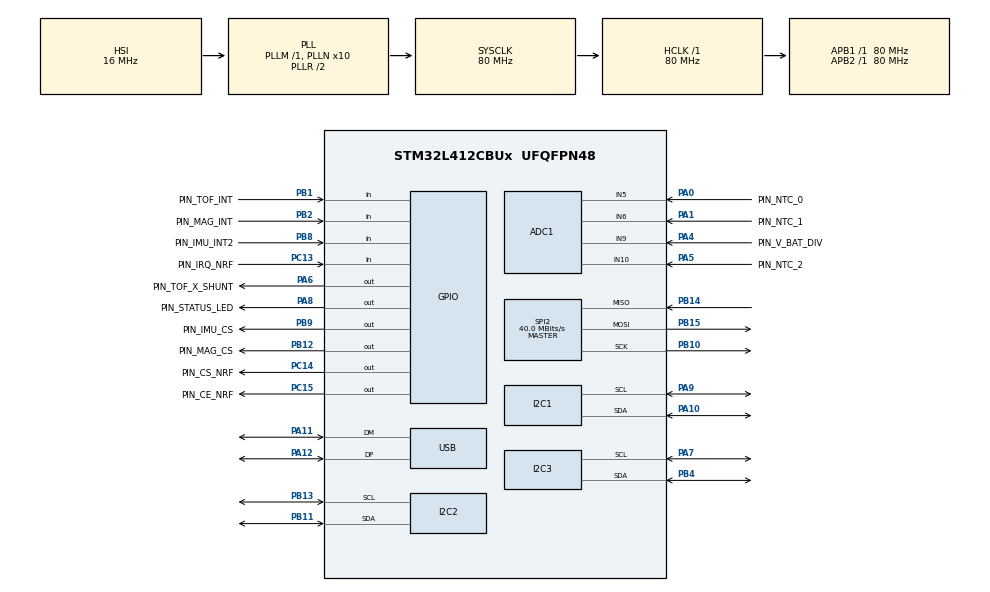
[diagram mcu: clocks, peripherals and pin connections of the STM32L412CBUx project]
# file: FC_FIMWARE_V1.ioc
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ADC1.Channel-1\#ChannelRegularConversion=ADC_CHANNEL_9
ADC1.NbrOfConversionFlag=1
ADC1.OffsetNumber-1\#ChannelRegularConversion=ADC_OFFSET_NONE
ADC1.Rank-1\#ChannelRegularConversion=1
ADC1.SamplingTime-1\#ChannelRegularConversion=ADC_SAMPLETIME_2CYCLES_5
ADC1.master=1
I2C1.Timing=0x10D19CE4
I2C2.Timing=0x10D19CE4
I2C3.Timing=0x10D19CE4
Mcu.Family=STM32L4
Mcu.Name=STM32L412CBUx
Mcu.Package=UFQFPN48
NVIC.PriorityGroup=NVIC_PRIORITYGROUP_4
NVIC.SPI2_IRQn=true\:0\:0\:false\:false\:true\:true\:true\:true
NVIC.USB_IRQn=true\:0\:0\:false\:false\:true\:false\:true\:true
PA0.GPIO_Label=PIN_NTC_0
PA0.Signal=ADCx_IN5
PA1.GPIO_Label=PIN_NTC_1
PA1.Signal=ADCx_IN6
PA10.Mode=I2C
PA10.Signal=I2C1_SDA
PA11.Mode=Device
PA11.Signal=USB_DM
PA12.Mode=Device
PA12.Signal=USB_DP
PA13\ (JTMS/SWDIO).Mode=Serial_Wire
PA13\ (JTMS/SWDIO).Signal=SYS_JTMS-SWDIO
PA14\ (JTCK/SWCLK).GPIO_Label=PIN_IMU_INT1
PA14\ (JTCK/SWCLK).Mode=Serial_Wire
PA14\ (JTCK/SWCLK).Signal=SYS_JTCK-SWCLK
PA4.GPIO_Label=PIN_V_BAT_DIV
PA4.Signal=ADCx_IN9
PA5.GPIO_Label=PIN_NTC_2
PA5.Signal=ADCx_IN10
PA6.GPIO_Label=PIN_TOF_X_SHUNT
PA6.Signal=GPIO_Output
PA7.Mode=I2C
PA7.Signal=I2C3_SCL
PA8.GPIO_Label=PIN_STATUS_LED
PA8.Signal=GPIO_Output
PA9.Mode=I2C
PA9.Signal=I2C1_SCL
PB1.GPIO_Label=PIN_TOF_INT
PB1.Signal=GPIO_Input
PB10.Mode=Full_Duplex_Master
PB10.Signal=SPI2_SCK
PB11.Mode=I2C
PB11.Signal=I2C2_SDA
PB12.GPIO_Label=PIN_MAG_CS
PB12.Signal=GPIO_Output
PB13.Mode=I2C
PB13.Signal=I2C2_SCL
PB14.Mode=Full_Duplex_Master
PB14.Signal=SPI2_MISO
PB15.Mode=Full_Duplex_Master
PB15.Signal=SPI2_MOSI
PB2.GPIO_Label=PIN_MAG_INT
PB2.Signal=GPIO_Input
PB4\ (NJTRST).Mode=I2C
PB4\ (NJTRST).Signal=I2C3_SDA
PB8.GPIO_Label=PIN_IMU_INT2
PB8.Signal=GPIO_Input
PB9.GPIO_Label=PIN_IMU_CS
PB9.Signal=GPIO_Output
PC13.GPIO_Label=PIN_IRQ_NRF
PC13.Signal=GPIO_Input
PC14-OSC32_IN\ (PC14).GPIO_Label=PIN_CS_NRF
PC14-OSC32_IN\ (PC14).Signal=GPIO_Output
PC15-OSC32_OUT\ (PC15).GPIO_Label=PIN_CE_NRF
PC15-OSC32_OUT\ (PC15).Signal=GPIO_Output
PH0-OSC_IN\ (PH0).Mode=HSE-External-Oscillator
PH0-OSC_IN\ (PH0).Signal=RCC_OSC_IN
PH1-OSC_OUT\ (PH1).Mode=HSE-External-Oscillator
PH1-OSC_OUT\ (PH1).Signal=RCC_OSC_OUT
ProjectManager.HeapSize=0x200
ProjectManager.StackSize=0x400
ProjectManager.TargetToolchain=CMake
RCC.ADCFreq_Value=80000000
RCC.AHBFreq_Value=80000000
RCC.APB1Freq_Value=80000000
RCC.APB1TimFreq_Value=80000000
RCC.APB2Freq_Value=80000000
RCC.APB2TimFreq_Value=80000000
RCC.CortexFreq_Value=80000000
RCC.HCLKFreq_Value=80000000
RCC.HSE_VALUE=12000000
RCC.HSI48_VALUE=48000000
RCC.HSI_VALUE=16000000
RCC.LSE_VALUE=32768
RCC.MSIClockRange=RCC_MSIRANGE_11
RCC.MSI_VALUE=48000000
RCC.PLLN=10
RCC.PLLSourceVirtual=RCC_PLLSOURCE_HSI
RCC.SYSCLKFreq_VALUE=80000000
RCC.SYSCLKSource=RCC_SYSCLKSOURCE_PLLCLK
RCC.USBFreq_Value=48000000
RCC.VCOOutputFreq_Value=160000000
SH.ADCx_IN10.0=ADC1_IN10,IN10-Single-Ended
SH.ADCx_IN5.0=ADC1_IN5,IN5-Single-Ended
SH.ADCx_IN6.0=ADC1_IN6,IN6-Single-Ended
SH.ADCx_IN9.0=ADC1_IN9,IN9-Single-Ended
SPI2.CalculateBaudRate=40.0 MBits/s
SPI2.DataSize=SPI_DATASIZE_8BIT
SPI2.Direction=SPI_DIRECTION_2LINES
SPI2.Mode=SPI_MODE_MASTER
SPI2.VirtualType=VM_MASTER
TIM2.AutoReloadPreload=TIM_AUTORELOAD_PRELOAD_DISABLE
TIM2.ClockDivision=TIM_CLOCKDIVISION_DIV1
TIM2.Prescaler=79
USB_DEVICE.CLASS_NAME_FS=CDC
USB_DEVICE.PRODUCT_STRING_CDC_FS=FC_V1
USB_DEVICE.USBD_DEBUG_LEVEL=3
USB_DEVICE.USBD_LPM_ENABLED=0
USB_DEVICE.VirtualMode=Cdc
USB_DEVICE.VirtualModeFS=Cdc_FS
VP_TIM2_VS_ClockSourceINT.Mode=Internal
VP_USB_DEVICE_VS_USB_DEVICE_CDC_FS.Mode=CDC_FS
board=custom

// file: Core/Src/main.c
/* USER CODE BEGIN Header */
/**
 ******************************************************************************
 * @file           : main.c
 * @brief          : Main program body
 ******************************************************************************
 * @attention
 *
 * Copyright (c) 2024 STMicroelectronics.
 * All rights reserved.
 *
 * This software is licensed under terms that can be found in the LICENSE file
 * in the root directory of this software component.
 * If no LICENSE file comes with this software, it is provided AS-IS.
 *
 * ./dfu-util/dfu-util -a 0 -i 0 -s 0x08000000:leave -D ./build/Debug/FC_FIMWARE_V1.bin
 *
 ******************************************************************************
 */
/* USER CODE END Header */
#include "main.h"
#include "usb_device.h"

/* USER CODE BEGIN Includes */
#include "usbd_cdc_if.h"
#include <stdio.h>
// #include ".\sensors\icm62670p\icm42670p.c"
// // #include "icm42670p.h"
#include "console.c" //needs to be here to compile
#include "console.h"
/* USER CODE END Includes */

ADC_HandleTypeDef hadc1;

I2C_HandleTypeDef hi2c1;
I2C_HandleTypeDef hi2c2;
I2C_HandleTypeDef hi2c3;

SPI_HandleTypeDef hspi2;

TIM_HandleTypeDef htim2;

void SystemClock_Config(void);
static void MX_GPIO_Init(void);
static void MX_ADC1_Init(void);
static void MX_I2C1_Init(void);
static void MX_I2C3_Init(void);
static void MX_SPI2_Init(void);
static void MX_I2C2_Init(void);
static void MX_TIM2_Init(void);

int main(void)
{

  /* MCU Configuration--------------------------------------------------------*/

  /* Reset of all peripherals, Initializes the Flash interface and the Systick. */
  HAL_Init();

  /* Configure the system clock */
  SystemClock_Config();

  /* Initialize all configured peripherals */
  MX_GPIO_Init();
  MX_ADC1_Init();
  MX_I2C1_Init();
  MX_I2C3_Init();
  MX_SPI2_Init();
  MX_USB_DEVICE_Init();
  MX_I2C2_Init();
  MX_TIM2_Init();
  /* USER CODE BEGIN 2 */
  // console_init();
  // set all SPI CS high
  HAL_GPIO_WritePin(PIN_CS_NRF_GPIO_Port, PIN_CS_NRF_Pin, GPIO_PIN_SET);
  HAL_GPIO_WritePin(PIN_IMU_CS_GPIO_Port, PIN_IMU_CS_Pin, GPIO_PIN_SET);
  // init sensors
  // icm_init();
  HAL_Delay(500);
  /* USER CODE END 2 */

  /* Infinite loop */
  /* USER CODE BEGIN WHILE */
  while (1)
  {
    // HAL_Delay(10);
    // toggle_status_LED(PIN_STATUS_LED_GPIO_Port, PIN_STATUS_LED_Pin);
    // console_check_for_messages();
    // debugf("oi\n");
    uint8_t TxBuffer[] = "Hello World! From STM32 USB CDC Device To Virtual COM Port\r\n";
    CDC_Transmit_FS(TxBuffer, sizeof(TxBuffer));
    // struct icm_data *data = icm_read_data();
    // free(data);

    // icm_read_data_fifo();

    /* USER CODE END WHILE */

  }
}

void SystemClock_Config(void)
{
  RCC_OscInitTypeDef RCC_OscInitStruct = {0};
  RCC_ClkInitTypeDef RCC_ClkInitStruct = {0};

  /** Configure the main internal regulator output voltage
   */
  if (HAL_PWREx_ControlVoltageScaling(PWR_REGULATOR_VOLTAGE_SCALE1) != HAL_OK)
  {
    Error_Handler();
  }

  /** Initializes the RCC Oscillators according to the specified parameters
   * in the RCC_OscInitTypeDef structure.
   */
  RCC_OscInitStruct.OscillatorType = RCC_OSCILLATORTYPE_HSI | RCC_OSCILLATORTYPE_MSI;
  RCC_OscInitStruct.HSIState = RCC_HSI_ON;
  RCC_OscInitStruct.HSICalibrationValue = RCC_HSICALIBRATION_DEFAULT;
  RCC_OscInitStruct.MSIState = RCC_MSI_ON;
  RCC_OscInitStruct.MSICalibrationValue = 0;
  RCC_OscInitStruct.MSIClockRange = RCC_MSIRANGE_11;
  RCC_OscInitStruct.PLL.PLLState = RCC_PLL_ON;
  RCC_OscInitStruct.PLL.PLLSource = RCC_PLLSOURCE_HSI;
  RCC_OscInitStruct.PLL.PLLM = 1;
  RCC_OscInitStruct.PLL.PLLN = 10;
  RCC_OscInitStruct.PLL.PLLQ = RCC_PLLQ_DIV2;
  RCC_OscInitStruct.PLL.PLLR = RCC_PLLR_DIV2;
  if (HAL_RCC_OscConfig(&RCC_OscInitStruct) != HAL_OK)
  {
    Error_Handler();
  }

  /** Initializes the CPU, AHB and APB buses clocks
   */
  RCC_ClkInitStruct.ClockType = RCC_CLOCKTYPE_HCLK | RCC_CLOCKTYPE_SYSCLK | RCC_CLOCKTYPE_PCLK1 | RCC_CLOCKTYPE_PCLK2;
  RCC_ClkInitStruct.SYSCLKSource = RCC_SYSCLKSOURCE_PLLCLK;
  RCC_ClkInitStruct.AHBCLKDivider = RCC_SYSCLK_DIV1;
  RCC_ClkInitStruct.APB1CLKDivider = RCC_HCLK_DIV1;
  RCC_ClkInitStruct.APB2CLKDivider = RCC_HCLK_DIV1;

  if (HAL_RCC_ClockConfig(&RCC_ClkInitStruct, FLASH_LATENCY_4) != HAL_OK)
  {
    Error_Handler();
  }
}

static void MX_ADC1_Init(void)
{

  ADC_MultiModeTypeDef multimode = {0};
  ADC_ChannelConfTypeDef sConfig = {0};

  /** Common config
   */
  hadc1.Instance = ADC1;
  hadc1.Init.ClockPrescaler = ADC_CLOCK_ASYNC_DIV1;
  hadc1.Init.Resolution = ADC_RESOLUTION_12B;
  hadc1.Init.DataAlign = ADC_DATAALIGN_RIGHT;
  hadc1.Init.ScanConvMode = ADC_SCAN_DISABLE;
  hadc1.Init.EOCSelection = ADC_EOC_SINGLE_CONV;
  hadc1.Init.LowPowerAutoWait = DISABLE;
  hadc1.Init.ContinuousConvMode = DISABLE;
  hadc1.Init.NbrOfConversion = 1;
  hadc1.Init.DiscontinuousConvMode = DISABLE;
  hadc1.Init.ExternalTrigConv = ADC_SOFTWARE_START;
  hadc1.Init.ExternalTrigConvEdge = ADC_EXTERNALTRIGCONVEDGE_NONE;
  hadc1.Init.DMAContinuousRequests = DISABLE;
  hadc1.Init.Overrun = ADC_OVR_DATA_PRESERVED;
  hadc1.Init.OversamplingMode = DISABLE;
  if (HAL_ADC_Init(&hadc1) != HAL_OK)
  {
    Error_Handler();
  }

  /** Configure the ADC multi-mode
   */
  multimode.Mode = ADC_MODE_INDEPENDENT;
  if (HAL_ADCEx_MultiModeConfigChannel(&hadc1, &multimode) != HAL_OK)
  {
    Error_Handler();
  }

  /** Configure Regular Channel
   */
  sConfig.Channel = ADC_CHANNEL_9;
  sConfig.Rank = ADC_REGULAR_RANK_1;
  sConfig.SamplingTime = ADC_SAMPLETIME_2CYCLES_5;
  sConfig.SingleDiff = ADC_SINGLE_ENDED;
  sConfig.OffsetNumber = ADC_OFFSET_NONE;
  sConfig.Offset = 0;
  if (HAL_ADC_ConfigChannel(&hadc1, &sConfig) != HAL_OK)
  {
    Error_Handler();
  }
}

static void MX_I2C1_Init(void)
{

  hi2c1.Instance = I2C1;
  hi2c1.Init.Timing = 0x10D19CE4;
  hi2c1.Init.OwnAddress1 = 0;
  hi2c1.Init.AddressingMode = I2C_ADDRESSINGMODE_7BIT;
  hi2c1.Init.DualAddressMode = I2C_DUALADDRESS_DISABLE;
  hi2c1.Init.OwnAddress2 = 0;
  hi2c1.Init.OwnAddress2Masks = I2C_OA2_NOMASK;
  hi2c1.Init.GeneralCallMode = I2C_GENERALCALL_DISABLE;
  hi2c1.Init.NoStretchMode = I2C_NOSTRETCH_DISABLE;
  if (HAL_I2C_Init(&hi2c1) != HAL_OK)
  {
    Error_Handler();
  }

  /** Configure Analogue filter
   */
  if (HAL_I2CEx_ConfigAnalogFilter(&hi2c1, I2C_ANALOGFILTER_ENABLE) != HAL_OK)
  {
    Error_Handler();
  }

  /** Configure Digital filter
   */
  if (HAL_I2CEx_ConfigDigitalFilter(&hi2c1, 0) != HAL_OK)
  {
    Error_Handler();
  }
}

static void MX_I2C2_Init(void)
{

  hi2c2.Instance = I2C2;
  hi2c2.Init.Timing = 0x10D19CE4;
  hi2c2.Init.OwnAddress1 = 0;
  hi2c2.Init.AddressingMode = I2C_ADDRESSINGMODE_7BIT;
  hi2c2.Init.DualAddressMode = I2C_DUALADDRESS_DISABLE;
  hi2c2.Init.OwnAddress2 = 0;
  hi2c2.Init.OwnAddress2Masks = I2C_OA2_NOMASK;
  hi2c2.Init.GeneralCallMode = I2C_GENERALCALL_DISABLE;
  hi2c2.Init.NoStretchMode = I2C_NOSTRETCH_DISABLE;
  if (HAL_I2C_Init(&hi2c2) != HAL_OK)
  {
    Error_Handler();
  }

  /** Configure Analogue filter
   */
  if (HAL_I2CEx_ConfigAnalogFilter(&hi2c2, I2C_ANALOGFILTER_ENABLE) != HAL_OK)
  {
    Error_Handler();
  }

  /** Configure Digital filter
   */
  if (HAL_I2CEx_ConfigDigitalFilter(&hi2c2, 0) != HAL_OK)
  {
    Error_Handler();
  }
}

static void MX_I2C3_Init(void)
{

  hi2c3.Instance = I2C3;
  hi2c3.Init.Timing = 0x10D19CE4;
  hi2c3.Init.OwnAddress1 = 0;
  hi2c3.Init.AddressingMode = I2C_ADDRESSINGMODE_7BIT;
  hi2c3.Init.DualAddressMode = I2C_DUALADDRESS_DISABLE;
  hi2c3.Init.OwnAddress2 = 0;
  hi2c3.Init.OwnAddress2Masks = I2C_OA2_NOMASK;
  hi2c3.Init.GeneralCallMode = I2C_GENERALCALL_DISABLE;
  hi2c3.Init.NoStretchMode = I2C_NOSTRETCH_DISABLE;
  if (HAL_I2C_Init(&hi2c3) != HAL_OK)
  {
    Error_Handler();
  }

  /** Configure Analogue filter
   */
  if (HAL_I2CEx_ConfigAnalogFilter(&hi2c3, I2C_ANALOGFILTER_ENABLE) != HAL_OK)
  {
    Error_Handler();
  }

  /** Configure Digital filter
   */
  if (HAL_I2CEx_ConfigDigitalFilter(&hi2c3, 0) != HAL_OK)
  {
    Error_Handler();
  }
}

static void MX_SPI2_Init(void)
{

  /* SPI2 parameter configuration*/
  hspi2.Instance = SPI2;
  hspi2.Init.Mode = SPI_MODE_MASTER;
  hspi2.Init.Direction = SPI_DIRECTION_2LINES;
  hspi2.Init.DataSize = SPI_DATASIZE_8BIT;
  hspi2.Init.CLKPolarity = SPI_POLARITY_LOW;
  hspi2.Init.CLKPhase = SPI_PHASE_1EDGE;
  hspi2.Init.NSS = SPI_NSS_SOFT;
  hspi2.Init.BaudRatePrescaler = SPI_BAUDRATEPRESCALER_2;
  hspi2.Init.FirstBit = SPI_FIRSTBIT_MSB;
  hspi2.Init.TIMode = SPI_TIMODE_DISABLE;
  hspi2.Init.CRCCalculation = SPI_CRCCALCULATION_DISABLE;
  hspi2.Init.CRCPolynomial = 7;
  hspi2.Init.CRCLength = SPI_CRC_LENGTH_DATASIZE;
  hspi2.Init.NSSPMode = SPI_NSS_PULSE_ENABLE;
  if (HAL_SPI_Init(&hspi2) != HAL_OK)
  {
    Error_Handler();
  }
}

static void MX_TIM2_Init(void)
{

  TIM_ClockConfigTypeDef sClockSourceConfig = {0};
  TIM_MasterConfigTypeDef sMasterConfig = {0};

  htim2.Instance = TIM2;
  htim2.Init.Prescaler = 79;
  htim2.Init.CounterMode = TIM_COUNTERMODE_UP;
  htim2.Init.Period = 4294967295;
  htim2.Init.ClockDivision = TIM_CLOCKDIVISION_DIV1;
  htim2.Init.AutoReloadPreload = TIM_AUTORELOAD_PRELOAD_DISABLE;
  if (HAL_TIM_Base_Init(&htim2) != HAL_OK)
  {
    Error_Handler();
  }
  sClockSourceConfig.ClockSource = TIM_CLOCKSOURCE_INTERNAL;
  if (HAL_TIM_ConfigClockSource(&htim2, &sClockSourceConfig) != HAL_OK)
  {
    Error_Handler();
  }
  sMasterConfig.MasterOutputTrigger = TIM_TRGO_RESET;
  sMasterConfig.MasterSlaveMode = TIM_MASTERSLAVEMODE_DISABLE;
  if (HAL_TIMEx_MasterConfigSynchronization(&htim2, &sMasterConfig) != HAL_OK)
  {
    Error_Handler();
  }
  /* USER CODE BEGIN TIM2_Init 2 */
  HAL_TIM_Base_Start(&htim2);
  /* USER CODE END TIM2_Init 2 */
}

static void MX_GPIO_Init(void)
{
  GPIO_InitTypeDef GPIO_InitStruct = {0};

  /* GPIO Ports Clock Enable */
  __HAL_RCC_GPIOC_CLK_ENABLE();
  __HAL_RCC_GPIOH_CLK_ENABLE();
  __HAL_RCC_GPIOA_CLK_ENABLE();
  __HAL_RCC_GPIOB_CLK_ENABLE();

  /*Configure GPIO pin Output Level */
  HAL_GPIO_WritePin(GPIOC, PIN_CS_NRF_Pin | PIN_CE_NRF_Pin, GPIO_PIN_RESET);

  /*Configure GPIO pin Output Level */
  HAL_GPIO_WritePin(GPIOA, PIN_TOF_X_SHUNT_Pin | PIN_STATUS_LED_Pin, GPIO_PIN_RESET);

  /*Configure GPIO pin Output Level */
  HAL_GPIO_WritePin(GPIOB, PIN_MAG_CS_Pin | PIN_IMU_CS_Pin, GPIO_PIN_RESET);

  /*Configure GPIO pin : PIN_IRQ_NRF_Pin */
  GPIO_InitStruct.Pin = PIN_IRQ_NRF_Pin;
  GPIO_InitStruct.Mode = GPIO_MODE_INPUT;
  GPIO_InitStruct.Pull = GPIO_NOPULL;
  HAL_GPIO_Init(PIN_IRQ_NRF_GPIO_Port, &GPIO_InitStruct);

  /*Configure GPIO pins : PIN_CS_NRF_Pin PIN_CE_NRF_Pin */
  GPIO_InitStruct.Pin = PIN_CS_NRF_Pin | PIN_CE_NRF_Pin;
  GPIO_InitStruct.Mode = GPIO_MODE_OUTPUT_PP;
  GPIO_InitStruct.Pull = GPIO_NOPULL;
  GPIO_InitStruct.Speed = GPIO_SPEED_FREQ_LOW;
  HAL_GPIO_Init(GPIOC, &GPIO_InitStruct);

  /*Configure GPIO pins : PIN_TOF_X_SHUNT_Pin PIN_STATUS_LED_Pin */
  GPIO_InitStruct.Pin = PIN_TOF_X_SHUNT_Pin | PIN_STATUS_LED_Pin;
  GPIO_InitStruct.Mode = GPIO_MODE_OUTPUT_PP;
  GPIO_InitStruct.Pull = GPIO_NOPULL;
  GPIO_InitStruct.Speed = GPIO_SPEED_FREQ_LOW;
  HAL_GPIO_Init(GPIOA, &GPIO_InitStruct);

  /*Configure GPIO pins : PIN_TOF_INT_Pin PIN_MAG_INT_Pin PIN_IMU_INT2_Pin */
  GPIO_InitStruct.Pin = PIN_TOF_INT_Pin | PIN_MAG_INT_Pin | PIN_IMU_INT2_Pin;
  GPIO_InitStruct.Mode = GPIO_MODE_INPUT;
  GPIO_InitStruct.Pull = GPIO_NOPULL;
  HAL_GPIO_Init(GPIOB, &GPIO_InitStruct);

  /*Configure GPIO pins : PIN_MAG_CS_Pin PIN_IMU_CS_Pin */
  GPIO_InitStruct.Pin = PIN_MAG_CS_Pin | PIN_IMU_CS_Pin;
  GPIO_InitStruct.Mode = GPIO_MODE_OUTPUT_PP;
  GPIO_InitStruct.Pull = GPIO_NOPULL;
  GPIO_InitStruct.Speed = GPIO_SPEED_FREQ_LOW;
  HAL_GPIO_Init(GPIOB, &GPIO_InitStruct);

}

void Error_Handler(void)
{
  __disable_irq();
  while (1)
  {
  }
}
